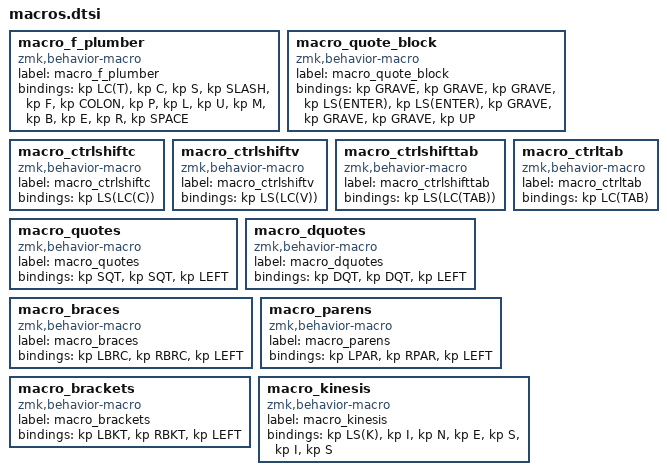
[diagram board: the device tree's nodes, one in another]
macro_f_plumber: macro_f_plumber{
compatible = "zmk,behavior-macro";
label = "macro_f_plumber";
#binding-cells = <0>;
bindings = <&kp LC(T)>, <&kp C>, <&kp S>, <&kp SLASH>, <&kp F>, <&kp COLON>, <&kp P>, <&kp L>, <&kp U>, <&kp M>, <&kp B>, <&kp E>, <&kp R>, <&kp SPACE>;
};
macro_quote_block: macro_quote_block{
compatible = "zmk,behavior-macro";
label = "macro_quote_block";
#binding-cells = <0>;
bindings = <&kp GRAVE>, <&kp GRAVE>, <&kp GRAVE>, <&kp LS(ENTER)>, <&kp LS(ENTER)>, <&kp GRAVE>, <&kp GRAVE>, <&kp GRAVE>, <&kp UP>;
};
macro_ctrlshiftc: macro_ctrlshiftc{
compatible = "zmk,behavior-macro";
label = "macro_ctrlshiftc";
#binding-cells = <0>;
bindings = <&kp LS(LC(C))>;
};
macro_ctrlshiftv: macro_ctrlshiftv{
compatible = "zmk,behavior-macro";
label = "macro_ctrlshiftv";
#binding-cells = <0>;
bindings = <&kp LS(LC(V))>;
};
macro_ctrlshifttab: macro_ctrlshifttab{
compatible = "zmk,behavior-macro";
label = "macro_ctrlshifttab";
#binding-cells = <0>;
bindings = <&kp LS(LC(TAB))>;
};
macro_ctrltab: macro_ctrltab{
compatible = "zmk,behavior-macro";
label = "macro_ctrltab";
#binding-cells = <0>;
bindings = <&kp LC(TAB)>;
};
macro_quotes: macro_quotes{
compatible = "zmk,behavior-macro";
label = "macro_quotes";
#binding-cells = <0>;
bindings = <&kp SQT>, <&kp SQT>, <&kp LEFT>;
};
macro_dquotes: macro_dquotes{
compatible = "zmk,behavior-macro";
label = "macro_dquotes";
#binding-cells = <0>;
bindings = <&kp DQT>, <&kp DQT>, <&kp LEFT>;
};
macro_braces: macro_braces{
compatible = "zmk,behavior-macro";
label = "macro_braces";
#binding-cells = <0>;
bindings = <&kp LBRC>, <&kp RBRC>, <&kp LEFT>;
};
macro_parens: macro_parens{
compatible = "zmk,behavior-macro";
label = "macro_parens";
#binding-cells = <0>;
bindings = <&kp LPAR>, <&kp RPAR>, <&kp LEFT>;
};
macro_brackets: macro_brackets{
compatible = "zmk,behavior-macro";
label = "macro_brackets";
#binding-cells = <0>;
bindings = <&kp LBKT>, <&kp RBKT>, <&kp LEFT>;
};
macro_kinesis: macro_kinesis{
compatible = "zmk,behavior-macro";
label = "macro_kinesis";
#binding-cells = <0>;
bindings = <&kp LS(K)>, <&kp I>, <&kp N>, <&kp E>, <&kp S>, <&kp I>, <&kp S>;
};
